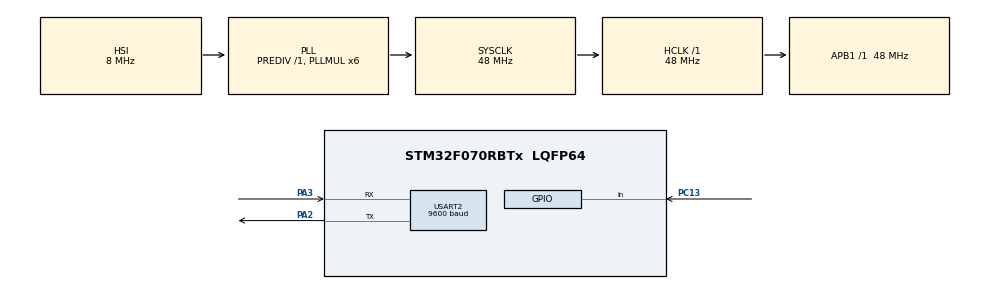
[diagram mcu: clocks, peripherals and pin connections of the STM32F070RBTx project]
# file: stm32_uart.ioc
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Mcu.Family=STM32F0
Mcu.Name=STM32F070RBTx
Mcu.Package=LQFP64
PA2.Mode=Asynchronous
PA2.Signal=USART2_TX
PA3.Mode=Asynchronous
PA3.Signal=USART2_RX
PC13.Signal=GPIO_Input
PF0-OSC_IN.Mode=HSE-External-Oscillator
PF0-OSC_IN.Signal=RCC_OSC_IN
PF1-OSC_OUT.Mode=HSE-External-Oscillator
PF1-OSC_OUT.Signal=RCC_OSC_OUT
ProjectManager.HeapSize=0x200
ProjectManager.StackSize=0x400
ProjectManager.TargetToolchain=STM32CubeIDE
RCC.AHBFreq_Value=48000000
RCC.APB1Freq_Value=48000000
RCC.APB1TimFreq_Value=48000000
RCC.HCLKFreq_Value=48000000
RCC.PLLMUL=RCC_PLL_MUL6
RCC.SYSCLKFreq_VALUE=48000000
RCC.SYSCLKSource=RCC_SYSCLKSOURCE_PLLCLK
USART2.BaudRate=9600
USART2.VirtualMode-Asynchronous=VM_ASYNC
board=custom

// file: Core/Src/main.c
/* USER CODE BEGIN Header */
/**
  ******************************************************************************
  * @file           : main.c
  * @brief          : Main program body
  ******************************************************************************
  * @attention
  *
  * <h2><center>&copy; Copyright (c) 2020 STMicroelectronics.
  * All rights reserved.</center></h2>
  *
  * This software component is licensed by ST under BSD 3-Clause license,
  * the "License"; You may not use this file except in compliance with the
  * License. You may obtain a copy of the License at:
  *                        opensource.org/licenses/BSD-3-Clause
  *
  ******************************************************************************
  */
/* USER CODE END Header */
#include "main.h"

/* USER CODE BEGIN Includes */
#include "stm32f070xb.h"
#include "stm32f0xx.h"
#include "stm32f0xx_hal.h"
/* USER CODE END Includes */

UART_HandleTypeDef huart2;

void SystemClock_Config(void);
static void MX_GPIO_Init(void);
static void MX_USART2_UART_Init(void);

/* USER CODE BEGIN 0 */
	uint32_t data[10];
/* USER CODE END 0 */

int main(void)
{
  /* USER CODE BEGIN 1 */
	char data[] = "Working good!\n";
	char data1[] = "Check!\n";
  /* USER CODE END 1 */

  /* MCU Configuration--------------------------------------------------------*/

  /* Reset of all peripherals, Initializes the Flash interface and the Systick. */
  HAL_Init();

  /* Configure the system clock */
  SystemClock_Config();

  /* Initialize all configured peripherals */
  MX_GPIO_Init();
  MX_USART2_UART_Init();

  /* Infinite loop */
  while (1)
  {

    /* USER CODE BEGIN 3 */
	  if (HAL_GPIO_ReadPin(GPIOC, GPIO_PIN_13)==GPIO_PIN_RESET) {
		 HAL_UART_Transmit(&huart2, data, sizeof(data), 250);
		 HAL_UART_Transmit(&huart2, data1, sizeof(data1), 250);
		 	 HAL_Delay(250);

	}
	  else {
		HAL_GPIO_ReadPin(GPIOC, GPIO_PIN_13)==GPIO_PIN_SET;
	}
  }
  /* USER CODE END 3 */
}

void SystemClock_Config(void)
{
  RCC_OscInitTypeDef RCC_OscInitStruct = {0};
  RCC_ClkInitTypeDef RCC_ClkInitStruct = {0};

  /** Initializes the RCC Oscillators according to the specified parameters
  * in the RCC_OscInitTypeDef structure.
  */
  RCC_OscInitStruct.OscillatorType = RCC_OSCILLATORTYPE_HSI;
  RCC_OscInitStruct.HSIState = RCC_HSI_ON;
  RCC_OscInitStruct.HSICalibrationValue = RCC_HSICALIBRATION_DEFAULT;
  RCC_OscInitStruct.PLL.PLLState = RCC_PLL_ON;
  RCC_OscInitStruct.PLL.PLLSource = RCC_PLLSOURCE_HSI;
  RCC_OscInitStruct.PLL.PLLMUL = RCC_PLL_MUL6;
  RCC_OscInitStruct.PLL.PREDIV = RCC_PREDIV_DIV1;
  if (HAL_RCC_OscConfig(&RCC_OscInitStruct) != HAL_OK)
  {
    Error_Handler();
  }
  /** Initializes the CPU, AHB and APB buses clocks
  */
  RCC_ClkInitStruct.ClockType = RCC_CLOCKTYPE_HCLK|RCC_CLOCKTYPE_SYSCLK
                              |RCC_CLOCKTYPE_PCLK1;
  RCC_ClkInitStruct.SYSCLKSource = RCC_SYSCLKSOURCE_PLLCLK;
  RCC_ClkInitStruct.AHBCLKDivider = RCC_SYSCLK_DIV1;
  RCC_ClkInitStruct.APB1CLKDivider = RCC_HCLK_DIV1;

  if (HAL_RCC_ClockConfig(&RCC_ClkInitStruct, FLASH_LATENCY_1) != HAL_OK)
  {
    Error_Handler();
  }
}

static void MX_USART2_UART_Init(void)
{

  huart2.Instance = USART2;
  huart2.Init.BaudRate = 9600;
  huart2.Init.WordLength = UART_WORDLENGTH_8B;
  huart2.Init.StopBits = UART_STOPBITS_1;
  huart2.Init.Parity = UART_PARITY_NONE;
  huart2.Init.Mode = UART_MODE_TX_RX;
  huart2.Init.HwFlowCtl = UART_HWCONTROL_NONE;
  huart2.Init.OverSampling = UART_OVERSAMPLING_16;
  huart2.Init.OneBitSampling = UART_ONE_BIT_SAMPLE_DISABLE;
  huart2.AdvancedInit.AdvFeatureInit = UART_ADVFEATURE_NO_INIT;
  if (HAL_UART_Init(&huart2) != HAL_OK)
  {
    Error_Handler();
  }

}

static void MX_GPIO_Init(void)
{
  GPIO_InitTypeDef GPIO_InitStruct = {0};

  /* GPIO Ports Clock Enable */
  __HAL_RCC_GPIOC_CLK_ENABLE();
  __HAL_RCC_GPIOF_CLK_ENABLE();
  __HAL_RCC_GPIOA_CLK_ENABLE();

  /*Configure GPIO pin : PC13 */
  GPIO_InitStruct.Pin = GPIO_PIN_13;
  GPIO_InitStruct.Mode = GPIO_MODE_INPUT;
  GPIO_InitStruct.Pull = GPIO_NOPULL;
  HAL_GPIO_Init(GPIOC, &GPIO_InitStruct);

}

void Error_Handler(void)
{
}

/************************ (C) COPYRIGHT STMicroelectronics *****END OF FILE****/
